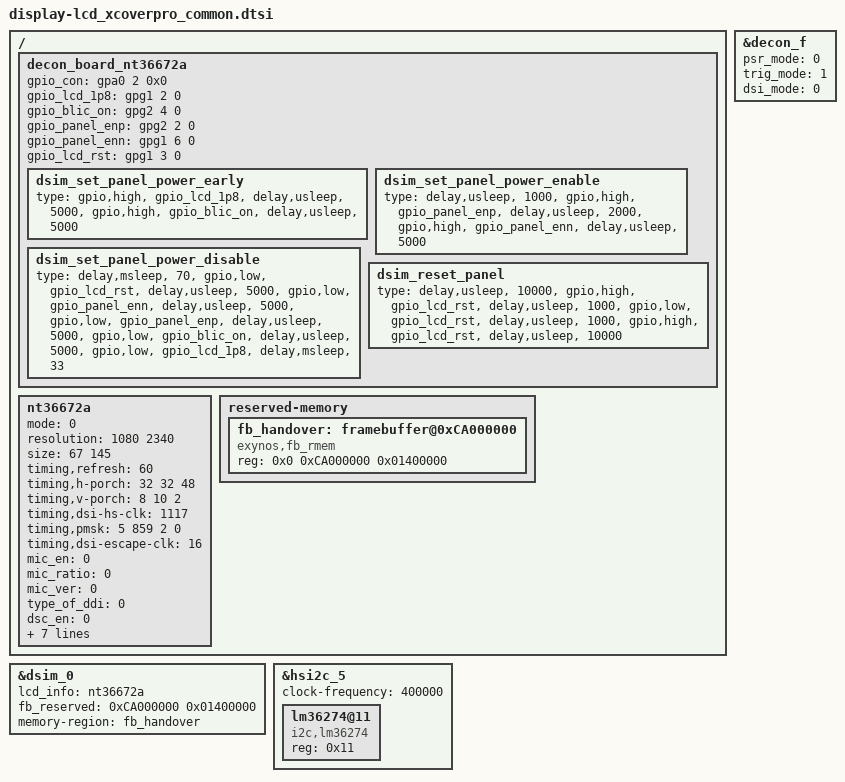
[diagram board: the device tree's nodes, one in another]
/*
 * SAMSUNG LCD Panel Device Tree Source
 *
 * Copyright (c) Samsung Electronics Co., Ltd.
 *		http://www.samsung.com
 *
 * This program is free software; you can redistribute it and/or modify
 * it under the terms of the GNU General Public License version 2 as
 * published by the Free Software Foundation.
 */

/ {
	fragment@lcd {
		target-path = "/";
		__overlay__ {
			decon_board_nt36672a: decon_board_nt36672a {
				gpio_con = <&gpa0 2 0x0>;	/* LCD_DET */

				gpio_lcd_1p8 = <&gpg1 2 0>;
				gpio_blic_on = <&gpg2 4 0>;
				gpio_panel_enp = <&gpg2 2 0>;
				gpio_panel_enn = <&gpg1 6 0>;
				gpio_lcd_rst = <&gpg1 3 0>;

				dsim_set_panel_power_early {
					type =
					"gpio,high",	"gpio_lcd_1p8",
					"delay,usleep",	"5000",
					"gpio,high",	"gpio_blic_on",
					"delay,usleep",	"5000";
				};
				dsim_set_panel_power_enable {
					type =
					"delay,usleep",	"1000",
					"gpio,high",	"gpio_panel_enp",
					"delay,usleep",	"2000",
					"gpio,high",	"gpio_panel_enn",
					"delay,usleep",	"5000";
				};
				dsim_set_panel_power_disable {
					type =
					"delay,msleep",	"70",
					"gpio,low",	"gpio_lcd_rst",
					"delay,usleep",	"5000",
					"gpio,low",	"gpio_panel_enn",
					"delay,usleep",	"5000",
					"gpio,low",	"gpio_panel_enp",
					"delay,usleep",	"5000",
					"gpio,low",	"gpio_blic_on",
					"delay,usleep",	"5000",
					"gpio,low",	"gpio_lcd_1p8",
					"delay,msleep",	"33";
				};
				dsim_reset_panel {
					type =
					"delay,usleep",	"10000",
					"gpio,high",	"gpio_lcd_rst",
					"delay,usleep",	"1000",
					"gpio,low",	"gpio_lcd_rst",
					"delay,usleep",	"1000",
					"gpio,high",	"gpio_lcd_rst",
					"delay,usleep",	"10000";
				};
			};

			nt36672a: nt36672a {
				mode = <0>; /* 0: video mode, 1: DP command mode, 2: MIPI command mode */
				resolution = <1080 2340>;
				size = <67 145>;	/* 67.068mm */	/* 145.314mm */
				timing,refresh = <60>;
				timing,h-porch = <32 32 48>;
				timing,v-porch = <8 10 2>;
				timing,dsi-hs-clk = <1117>;
				timing,pmsk = <5 859 2 0>;
				timing,dsi-escape-clk = <16>;
				mic_en = <0>;		/* 0: Disable, 1: Enable */
				mic_ratio = <0>;	/* 0: 1/2 mic, 1: 1/3 mic */
				mic_ver = <0>;		/* 0: mic v1.1, 1: v1.2, 2: v2.0 */
				type_of_ddi = <0>;	/* 0: Samsung Mobile, 1: MAGNA, 2: Normal(Etc) */
				dsc_en = <0>;		/* 0: Disable, 1: Enable */
				dsc_cnt = <0>;		/* used DSC count */
				dsc_slice_num = <0>;	/* count of dsc slice */
				data_lane = <4>;	/* number of using data lane */
				mres_en = <0>;
				clklane_onoff = <1>;	/* 0: Disable, 1: Enable */
				vt_compensation = <0>;	/* for difference between wordclk and vclk at video mode */
				decon_board = <&decon_board_nt36672a>;
			};

			reserved-memory {
				fb_handover: framebuffer@0xCA000000 {
					compatible = "exynos,fb_rmem";
					reg = <0x0 0xCA000000 0x01400000>;
				};
			};
		};
	};
};

&dsim_0 {
	lcd_info = <&nt36672a>;
	fb_reserved = <0xCA000000 0x01400000>; /* iovmm_map_oto */
	memory-region = <&fb_handover>;	/* rmem */
};

&decon_f {
	psr_mode = <0>;		/* 0: video mode, 1: DP command mode, 2: MIPI command mode */
	trig_mode = <1>;	/* 0: hw trigger, 1: sw trigger */
	dsi_mode = <0>;		/* 0: single dsi, 1: dual dsi */
};

/* hsi2c_5: hsi2c@11D30000 */
&hsi2c_5 {
	clock-frequency = <400000>;
	status = "okay";

	lm36274@11 {
		compatible = "i2c,lm36274";
		reg = <0x11>;
	};
};

